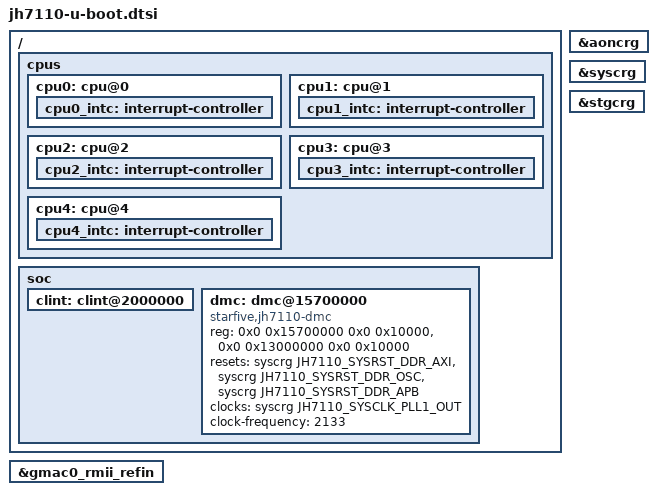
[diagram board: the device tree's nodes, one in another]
// SPDX-License-Identifier: GPL-2.0 OR MIT
/*
 * Copyright (C) 2022 StarFive Technology Co., Ltd.
 */

#include <dt-bindings/reset/starfive-jh7110.h>

/ {
	cpus: cpus {
		u-boot,dm-spl;

		cpu0: cpu@0 {
			u-boot,dm-spl;
			status = "okay";
			cpu0_intc: interrupt-controller {
				u-boot,dm-spl;
			};
		};

		cpu1: cpu@1 {
			u-boot,dm-spl;
			cpu1_intc: interrupt-controller {
				u-boot,dm-spl;
			};
		};

		cpu2: cpu@2 {
			u-boot,dm-spl;
			cpu2_intc: interrupt-controller {
				u-boot,dm-spl;
			};
		};

		cpu3: cpu@3 {
			u-boot,dm-spl;
			cpu3_intc: interrupt-controller {
				u-boot,dm-spl;
			};
		};

		cpu4: cpu@4 {
			u-boot,dm-spl;
			cpu4_intc: interrupt-controller {
				u-boot,dm-spl;
			};
		};
	};

	soc {
		u-boot,dm-spl;

		clint: clint@2000000 {
			u-boot,dm-spl;
		};

		dmc: dmc@15700000 {
			u-boot,dm-spl;
			compatible = "starfive,jh7110-dmc";
			reg = <0x0 0x15700000 0x0 0x10000>,
				<0x0 0x13000000 0x0 0x10000>;
			resets = <&syscrg JH7110_SYSRST_DDR_AXI>,
				<&syscrg JH7110_SYSRST_DDR_OSC>,
				<&syscrg JH7110_SYSRST_DDR_APB>;
			reset-names = "axi", "osc", "apb";
			clocks = <&syscrg JH7110_SYSCLK_PLL1_OUT>;
			clock-names = "pll1";
			clock-frequency = <2133>;
		};
	};
};

&gmac0_rmii_refin {
	u-boot,dm-spl;
};

&aoncrg {
	u-boot,dm-spl;
};

&syscrg {
	u-boot,dm-spl;
};

&stgcrg {
	u-boot,dm-spl;
};
